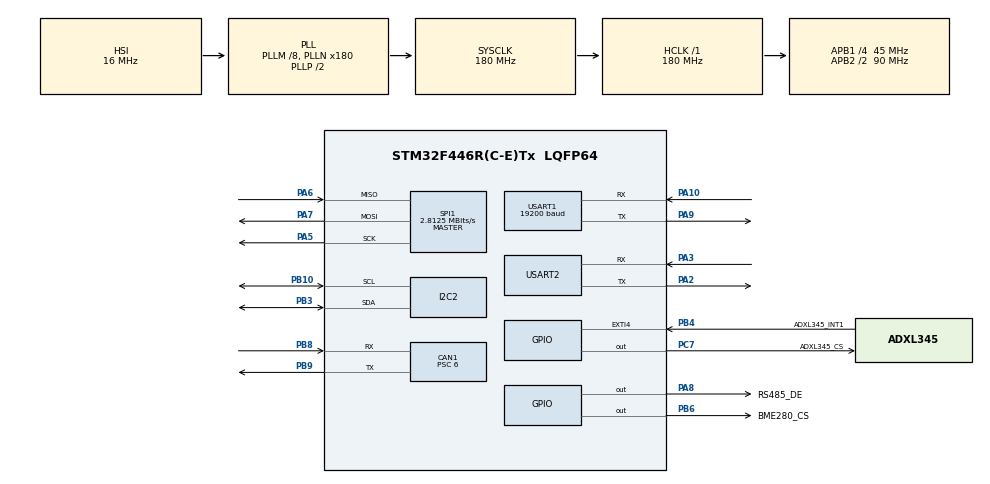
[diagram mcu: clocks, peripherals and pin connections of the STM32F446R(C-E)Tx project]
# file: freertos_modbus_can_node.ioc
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CAN1.BS1=CAN_BS1_12TQ
CAN1.BS2=CAN_BS2_2TQ
CAN1.CalculateBaudRate=500000
CAN1.CalculateTimeBit=2000
CAN1.CalculateTimeQuantum=133.33333333333331
CAN1.NART=ENABLE
CAN1.Prescaler=6
Dma.Request0=USART1_RX
Dma.Request1=USART1_TX
Dma.USART1_RX.0.Direction=DMA_PERIPH_TO_MEMORY
Dma.USART1_RX.0.FIFOMode=DMA_FIFOMODE_DISABLE
Dma.USART1_RX.0.Instance=DMA2_Stream2
Dma.USART1_RX.0.MemDataAlignment=DMA_MDATAALIGN_BYTE
Dma.USART1_RX.0.MemInc=DMA_MINC_ENABLE
Dma.USART1_RX.0.Mode=DMA_NORMAL
Dma.USART1_RX.0.PeriphDataAlignment=DMA_PDATAALIGN_BYTE
Dma.USART1_RX.0.PeriphInc=DMA_PINC_DISABLE
Dma.USART1_RX.0.Priority=DMA_PRIORITY_LOW
Dma.USART1_TX.1.Direction=DMA_MEMORY_TO_PERIPH
Dma.USART1_TX.1.FIFOMode=DMA_FIFOMODE_DISABLE
Dma.USART1_TX.1.Instance=DMA2_Stream7
Dma.USART1_TX.1.MemDataAlignment=DMA_MDATAALIGN_BYTE
Dma.USART1_TX.1.MemInc=DMA_MINC_ENABLE
Dma.USART1_TX.1.Mode=DMA_NORMAL
Dma.USART1_TX.1.PeriphDataAlignment=DMA_PDATAALIGN_BYTE
Dma.USART1_TX.1.PeriphInc=DMA_PINC_DISABLE
Dma.USART1_TX.1.Priority=DMA_PRIORITY_LOW
IWDG.Prescaler=IWDG_PRESCALER_256
IWDG.Reload=999
Mcu.Family=STM32F4
Mcu.Name=STM32F446R(C-E)Tx
Mcu.Package=LQFP64
NVIC.CAN1_RX0_IRQn=true\:6\:0\:true\:false\:true\:true\:true\:true
NVIC.CAN1_SCE_IRQn=true\:6\:0\:true\:false\:true\:true\:true\:true
NVIC.CAN1_TX_IRQn=true\:6\:0\:true\:false\:true\:true\:true\:true
NVIC.DMA2_Stream2_IRQn=true\:6\:0\:true\:false\:true\:false\:true\:true
NVIC.DMA2_Stream7_IRQn=true\:6\:0\:true\:false\:true\:false\:true\:true
NVIC.EXTI4_IRQn=true\:6\:0\:true\:false\:true\:true\:true\:true
NVIC.PriorityGroup=NVIC_PRIORITYGROUP_4
NVIC.TIM6_DAC_IRQn=true\:0\:0\:false\:false\:true\:false\:true\:true
NVIC.TimeBase=TIM6_DAC_IRQn
NVIC.TimeBaseIP=TIM6
NVIC.USART1_IRQn=true\:6\:0\:true\:false\:true\:true\:true\:true
PA10.Mode=Asynchronous
PA10.Signal=USART1_RX
PA13.Mode=Serial_Wire
PA13.Signal=SYS_JTMS-SWDIO
PA14.Mode=Serial_Wire
PA14.Signal=SYS_JTCK-SWCLK
PA2.Mode=Asynchronous
PA2.Signal=USART2_TX
PA3.Mode=Asynchronous
PA3.Signal=USART2_RX
PA5.Mode=Full_Duplex_Master
PA5.Signal=SPI1_SCK
PA6.Mode=Full_Duplex_Master
PA6.Signal=SPI1_MISO
PA7.Mode=Full_Duplex_Master
PA7.Signal=SPI1_MOSI
PA8.GPIO_Label=RS485_DE
PA8.PinState=GPIO_PIN_RESET
PA8.Signal=GPIO_Output
PA9.Mode=Asynchronous
PA9.Signal=USART1_TX
PB10.Mode=I2C
PB10.Signal=I2C2_SCL
PB3.Mode=I2C
PB3.Signal=I2C2_SDA
PB4.GPIO_Label=ADXL345_INT1
PB4.GPIO_ModeDefaultEXTI=GPIO_MODE_IT_RISING
PB4.GPIO_PuPd=GPIO_PULLDOWN
PB4.Signal=GPXTI4
PB6.GPIO_Label=BME280_CS
PB6.PinState=GPIO_PIN_SET
PB6.Signal=GPIO_Output
PB8.Mode=CAN_Activate
PB8.Signal=CAN1_RX
PB9.Mode=CAN_Activate
PB9.Signal=CAN1_TX
PC7.GPIO_Label=ADXL345_CS
PC7.PinState=GPIO_PIN_SET
PC7.Signal=GPIO_Output
ProjectManager.HeapSize=0x200
ProjectManager.StackSize=0x400
ProjectManager.TargetToolchain=CMake
RCC.AHBFreq_Value=180000000
RCC.APB1CLKDivider=RCC_HCLK_DIV4
RCC.APB1Freq_Value=45000000
RCC.APB1TimFreq_Value=90000000
RCC.APB2CLKDivider=RCC_HCLK_DIV2
RCC.APB2Freq_Value=90000000
RCC.APB2TimFreq_Value=180000000
RCC.CortexFreq_Value=180000000
RCC.FLatency-AdvancedSettings=FLASH_LATENCY_5
RCC.HCLKFreq_Value=180000000
RCC.HSE_VALUE=8000000
RCC.HSI_VALUE=16000000
RCC.LSE_VALUE=32768
RCC.PLLM=8
RCC.PLLN=180
RCC.SYSCLKFreq_VALUE=180000000
RCC.SYSCLKSource=RCC_SYSCLKSOURCE_PLLCLK
RCC.USBFreq_Value=180000000
RCC.VCOOutputFreq_Value=360000000
SPI1.BaudRatePrescaler=SPI_BAUDRATEPRESCALER_32
SPI1.CLKPhase=SPI_PHASE_2EDGE
SPI1.CLKPolarity=SPI_POLARITY_HIGH
SPI1.CalculateBaudRate=2.8125 MBits/s
SPI1.Direction=SPI_DIRECTION_2LINES
SPI1.Mode=SPI_MODE_MASTER
SPI1.VirtualType=VM_MASTER
USART1.BaudRate=19200
USART1.Parity=PARITY_EVEN
USART1.VirtualMode=VM_ASYNC
USART1.WordLength=WORDLENGTH_9B
USART2.VirtualMode=VM_ASYNC
VP_IWDG_VS_IWDG.Mode=IWDG_Activate
VP_SYS_VS_tim6.Mode=TIM6
board=NUCLEO-F446RE

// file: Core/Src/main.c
/* USER CODE BEGIN Header */
/**
  ******************************************************************************
  * @file           : main.c
  * @brief          : Main program body
  ******************************************************************************
  * @attention
  *
  * Copyright (c) 2026 STMicroelectronics.
  * All rights reserved.
  *
  * This software is licensed under terms that can be found in the LICENSE file
  * in the root directory of this software component.
  * If no LICENSE file comes with this software, it is provided AS-IS.
  *
  ******************************************************************************
  */
/* USER CODE END Header */
#include "main.h"
#include "can.h"
#include "dma.h"
#include "i2c.h"
#include "iwdg.h"
#include "spi.h"
#include "usart.h"
#include "gpio.h"

/* USER CODE BEGIN Includes */
#include "app_boot.h"
#include "app_rtos.h"
#include "FreeRTOS.h"
#include "task.h"

/* USER CODE END Includes */

void SystemClock_Config(void);

int main(void)
{

  /* MCU Configuration--------------------------------------------------------*/

  /* Reset of all peripherals, Initializes the Flash interface and the Systick. */
  HAL_Init();

  /* Configure the system clock */
  SystemClock_Config();

  /* Initialize all configured peripherals */
  MX_GPIO_Init();
  MX_DMA_Init();
  MX_CAN1_Init();
  MX_I2C2_Init();
  MX_SPI1_Init();
  MX_USART1_UART_Init();
  MX_USART2_UART_Init();
  MX_IWDG_Init();
  /* USER CODE BEGIN 2 */
  if (app_boot_initialize() != APP_BOOT_OK)
  {
    Error_Handler();
  }
  if (app_rtos_initialize() != APP_RTOS_OK)
  {
    Error_Handler();
  }
  vTaskStartScheduler();
  app_rtos_fail_stop(APP_RTOS_FAULT_SCHEDULER_RETURN);

  /* USER CODE END 2 */

  /* Infinite loop */
  while (1)
  {

  }
}

void SystemClock_Config(void)
{
  RCC_OscInitTypeDef RCC_OscInitStruct = {0};
  RCC_ClkInitTypeDef RCC_ClkInitStruct = {0};

  /** Configure the main internal regulator output voltage
  */
  __HAL_RCC_PWR_CLK_ENABLE();
  __HAL_PWR_VOLTAGESCALING_CONFIG(PWR_REGULATOR_VOLTAGE_SCALE1);

  /** Initializes the RCC Oscillators according to the specified parameters
  * in the RCC_OscInitTypeDef structure.
  */
  RCC_OscInitStruct.OscillatorType = RCC_OSCILLATORTYPE_HSI|RCC_OSCILLATORTYPE_LSI;
  RCC_OscInitStruct.HSIState = RCC_HSI_ON;
  RCC_OscInitStruct.HSICalibrationValue = RCC_HSICALIBRATION_DEFAULT;
  RCC_OscInitStruct.LSIState = RCC_LSI_ON;
  RCC_OscInitStruct.PLL.PLLState = RCC_PLL_ON;
  RCC_OscInitStruct.PLL.PLLSource = RCC_PLLSOURCE_HSI;
  RCC_OscInitStruct.PLL.PLLM = 8;
  RCC_OscInitStruct.PLL.PLLN = 180;
  RCC_OscInitStruct.PLL.PLLP = RCC_PLLP_DIV2;
  RCC_OscInitStruct.PLL.PLLQ = 2;
  RCC_OscInitStruct.PLL.PLLR = 2;
  if (HAL_RCC_OscConfig(&RCC_OscInitStruct) != HAL_OK)
  {
    Error_Handler();
  }

  /** Activate the Over-Drive mode
  */
  if (HAL_PWREx_EnableOverDrive() != HAL_OK)
  {
    Error_Handler();
  }

  /** Initializes the CPU, AHB and APB buses clocks
  */
  RCC_ClkInitStruct.ClockType = RCC_CLOCKTYPE_HCLK|RCC_CLOCKTYPE_SYSCLK
                              |RCC_CLOCKTYPE_PCLK1|RCC_CLOCKTYPE_PCLK2;
  RCC_ClkInitStruct.SYSCLKSource = RCC_SYSCLKSOURCE_PLLCLK;
  RCC_ClkInitStruct.AHBCLKDivider = RCC_SYSCLK_DIV1;
  RCC_ClkInitStruct.APB1CLKDivider = RCC_HCLK_DIV4;
  RCC_ClkInitStruct.APB2CLKDivider = RCC_HCLK_DIV2;

  if (HAL_RCC_ClockConfig(&RCC_ClkInitStruct, FLASH_LATENCY_5) != HAL_OK)
  {
    Error_Handler();
  }
}

void HAL_TIM_PeriodElapsedCallback(TIM_HandleTypeDef *htim)
{
  if (htim->Instance == TIM6)
  {
    HAL_IncTick();
  }
}

void Error_Handler(void)
{
  __disable_irq();
  while (1)
  {
  }
}
